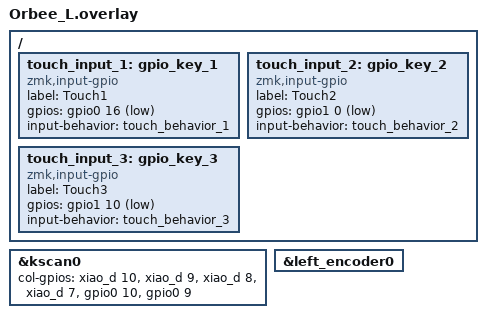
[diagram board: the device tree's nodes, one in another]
#include "Orbee.dtsi"

&kscan0 {
    col-gpios = 
        <&xiao_d 10 GPIO_ACTIVE_HIGH>,
        <&xiao_d 9 GPIO_ACTIVE_HIGH>,
        <&xiao_d 8 GPIO_ACTIVE_HIGH>,
        <&xiao_d 7 GPIO_ACTIVE_HIGH>,
        <&gpio0 10 GPIO_ACTIVE_HIGH>,
        <&gpio0 9 GPIO_ACTIVE_HIGH>;
};

&left_encoder0 {
    status = "okay";
};

/ {
   
    touch_input_1: gpio_key_1 {
        compatible = "zmk,input-gpio";
        label = "Touch1";
        gpios = <&gpio0 16 GPIO_ACTIVE_LOW>;
        input-behavior = <&touch_behavior_1>;
    };

    touch_input_2: gpio_key_2 {
        compatible = "zmk,input-gpio";
        label = "Touch2";
        gpios = <&gpio1 0 GPIO_ACTIVE_LOW>;
        input-behavior = <&touch_behavior_2>;
    };

    touch_input_3: gpio_key_3 {
        compatible = "zmk,input-gpio";
        label = "Touch3";
        gpios = <&gpio1 10 GPIO_ACTIVE_LOW>;
        input-behavior = <&touch_behavior_3>;
    };
};
